# PRU_ICSS_0_ECAP_local register map
Vendor: Texas Instruments
Peripheral module from a debugger description file (folder 66AK2G0x_66AK2G1x).
Registers are 32-bit, read-write, reset 0x0 unless marked. A register's access mark holds for its fields unless they carry their own. Offsets are as the file gives them; lines under a group give offsets from that group; [hi:lo] are bit positions; {n}, {i} and the like mark numbered series; 'fields as' and 'values as' point back to an identical list; <NAME> marks a mode.

## PRU_ICSS_0_ECAP
0x00 PRUSS_ECAP_TSCNT
  [31:0] TSCNT — Active 32 bit-counter register that is used as the capture time-base
0x04 PRUSS_ECAP_CNTPHS
  [31:0] CNTPHS — Counter phase value register that can be programmed for phase lag/lead. This register shadows TSCNT and is loaded into
0x08 PRUSS_ECAP_CAP1
  [31:0] CAP1 — This register can be loaded (written) by the following. (a) Time-Stamp (that is, counter value) during a capture event. (b) Software may be useful for test purposes. (c) APRD active register when used in APWM mode.
0x0C PRUSS_ECAP_CAP2
  [31:0] CAP2 — This register can be loaded (written) by the following. (a) Time- Stamp (that is, counter value) during a capture event. (b) Software may be useful for test purposes. (c) APRD active register when used in APWM mode.
0x10 PRUSS_ECAP_CAP3
  [31:0] CAP3 — In CMP mode, this is a time-stamp capture register. In APWM mode, this is the period shadow (APRD) register. User software updates the PWM period value through this register. In this mode, CAP3 shadows CAP1.
0x14 PRUSS_ECAP_CAP4
  [31:0] CAP4 — In CMP mode, this is a time-stamp capture register. In APWM mode, this is the compare shadow (ACMP) register. User software updates the PWM compare value through this register. In this mode, CAP4 shadows CAP2.
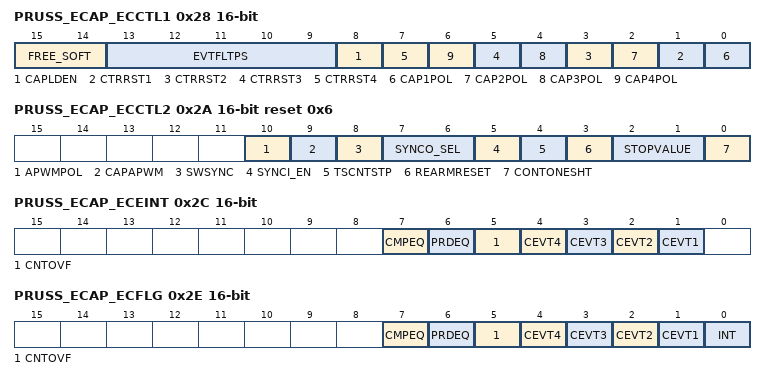
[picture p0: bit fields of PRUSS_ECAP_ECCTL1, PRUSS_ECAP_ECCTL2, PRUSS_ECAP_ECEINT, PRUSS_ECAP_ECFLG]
0x28 PRUSS_ECAP_ECCTL1 16-bit
  [15:14] FREE_SOFT — Emulation Control
  [13:9] EVTFLTPS — Event Filter prescale select:
  [8] CAPLDEN — Enable Loading of
  [2n-1] CTRRST{n} (n=1..4) — Counter Reset on Capture Event {n}
  [2n-2] CAP{n}POL (n=1..4) — Capture Event {n} Polarity select
0x2A PRUSS_ECAP_ECCTL2 16-bit access per field reset 0x6
  [10] APWMPOL rw
  [9] CAPAPWM rw
  [8] SWSYNC rw — Software-forced Counter (TSCNT) Synchronizing. This provides a convenient software method to synchronize some or all ECAP time bases. In APWM mode, the synchronizing can also be done via the CTR = PRD event. Note: Selection CTR = PRD is meaningful only in APWM mode. However, you can choose it in CAP mode if you find doing so useful.
  [7:6] SYNCO_SEL rw — Sync-Out Select
  [5] SYNCI_EN rw
  [4] TSCNTSTP rw
  [3] REARMRESET rw
  [2:1] STOPVALUE rw
  [0] CONTONESHT rw
0x2C PRUSS_ECAP_ECEINT 16-bit access per field
  [7] CMPEQ rw, [6] PRDEQ rw, [5] CNTOVF rw, [n] CEVT{n} rw (n=1..4)
0x2E PRUSS_ECAP_ECFLG 16-bit ro
  [7] CMPEQ, [6] PRDEQ, [5] CNTOVF, [n] CEVT{n} (n=1..4), [0] INT
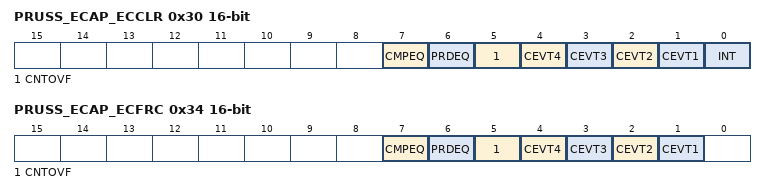
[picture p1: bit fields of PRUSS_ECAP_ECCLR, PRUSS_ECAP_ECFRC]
0x30 PRUSS_ECAP_ECCLR 16-bit access per field
  [7] CMPEQ rw, [6] PRDEQ rw, [5] CNTOVF rw, [n] CEVT{n} rw (n=1..4), [0] INT rw
0x34 PRUSS_ECAP_ECFRC 16-bit access per field
  [7] CMPEQ rw, [6] PRDEQ rw, [5] CNTOVF rw, [n] CEVT{n} rw (n=1..4)
0x5C PRUSS_ECAP_PID ro reset not defined
  [31:0] REVISION — IP Revision
